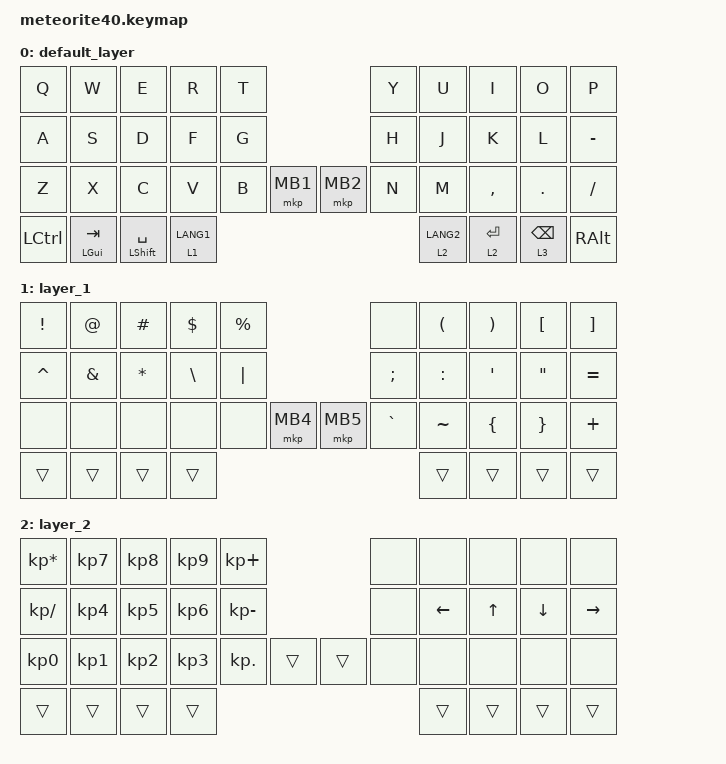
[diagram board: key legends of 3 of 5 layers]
#include <behaviors.dtsi>
#include <dt-bindings/zmk/bt.h>
#include <dt-bindings/zmk/keys.h>
#include <dt-bindings/zmk/pointing.h>

/ {
    keymap {
        compatible = "zmk,keymap";

        default_layer {
            bindings = <
                &kp Q  &kp W  &kp E  &kp R  &kp T                     &kp Y  &kp U  &kp I  &kp O  &kp P
                &kp A  &kp S  &kp D  &kp F  &kp G                     &kp H  &kp J  &kp K  &kp L  &kp MINUS
                &kp Z  &kp X  &kp C  &kp V  &kp B  &mkp MB1 &mkp MB2  &kp N  &kp M  &kp COMMA &kp DOT &kp SLASH
                &kp LCTRL &mt LGUI TAB &mt LSHIFT SPACE &lt 1 LANG1 &lt 2 LANG2 &lt 2 ENTER &lt 3 BSPC &kp RALT
            >;

            sensor-bindings =
                <&inc_dec_kp LG(MINUS) LG(EQUAL)>,   // RE0: cmd + - / +
                <&inc_dec_kp C_VOL_DN C_VOL_UP>;     // RE1: volume down/up
        };

        layer_1 {
            bindings = <
                &kp EXCL  &kp AT   &kp HASH &kp DLLR &kp PRCNT                    &none     &kp LPAR  &kp RPAR &kp LBKT &kp RBKT
                &kp CARET &kp AMPS &kp STAR &kp BSLH &kp PIPE                     &kp SEMI  &kp COLON &kp SQT  &kp DQT  &kp EQUAL
                &none     &none    &none    &none    &none     &mkp MB4 &mkp MB5  &kp GRAVE &kp TILDE &kp LBRC &kp RBRC &kp PLUS
                                   &trans   &trans   &trans    &trans   &trans    &trans    &trans    &trans
            >;
        };

        layer_2 {
            bindings = <
                &kp KP_MULTIPLY &kp KP_N7 &kp KP_N8 &kp KP_N9 &kp KP_PLUS                   &none  &none    &none   &none    &none
                &kp KP_DIVIDE   &kp KP_N4 &kp KP_N5 &kp KP_N6 &kp KP_MINUS                  &none  &kp LEFT &kp UP  &kp DOWN &kp RIGHT
                &kp KP_N0       &kp KP_N1 &kp KP_N2 &kp KP_N3 &kp KP_DOT     &trans &trans  &none  &none    &none   &none    &none
                                           &trans   &trans    &trans         &trans &trans  &trans &trans   &trans            
            >;
        };

        layer_3 {
            bindings = <
                &kp F1  &kp F2  &kp F3  &kp F4  &kp F5                  &kp F6  &kp F7  &kp F8  &kp F9  &kp F10
                &none   &none   &none   &none   &none                   &none   &none   &none   &none   &none
                &none   &none   &none   &none   &none                   &none   &none   &none   &none   &none                
                                &trans  &trans  &trans  &trans  &trans  &trans  &trans  &trans            
            >;
        };

        layer_4 {
            bindings = <
                &none   &none   &none   &none   &none                   &none   &none   &none   &none   &none
                &none   &none   &none   &none   &none                   &none   &none   &none   &none   &none
                &none   &none   &none   &none   &none                   &none   &none   &none   &none   &none                
                                &trans  &trans  &trans  &trans  &trans  &trans  &trans  &trans             
            >;
        };
    };
};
